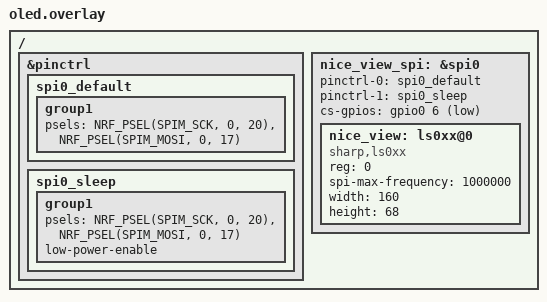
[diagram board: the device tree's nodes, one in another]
/ {

        &pinctrl {
        spi0_default: spi0_default {
                group1 {
                /* P0.20 = (0, 20) and P0.17 = (0, 17) */
                psels = <NRF_PSEL(SPIM_SCK, 0, 20)>,
                        <NRF_PSEL(SPIM_MOSI, 0, 17)>;
                };
        };
        spi0_sleep: spi0_sleep {
                group1 {
                /* main role: configure P0.01 as SPI clock, P0.02 as SPI MOSI, P0.03 as SPI MISO */
                psels = <NRF_PSEL(SPIM_SCK, 0, 20)>,
                        <NRF_PSEL(SPIM_MOSI, 0, 17)>;
                low-power-enable;
                };
                };

        };

        &spi0 {
                status = "okay";
                pinctrl-0 = < &spi0_default >;
                pinctrl-1 = < &spi0_sleep >;
                pinctrl-names = "default", "sleep";
                /* P0.06 = &gpio0 6 */
                cs-gpios = < &gpio0 6 GPIO_ACTIVE_LOW >;
                /* nice!view display definition */
                nice_view: ls0xx@0 {
                        compatible = "sharp,ls0xx";
                        reg = <0>; /* Matches the first CS pin in cs-gpios */
                        spi-max-frequency = <1000000>;
                        width = <160>;
                        height = <68>;
                };
        };

        nice_view_spi: &spi0 {};
}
